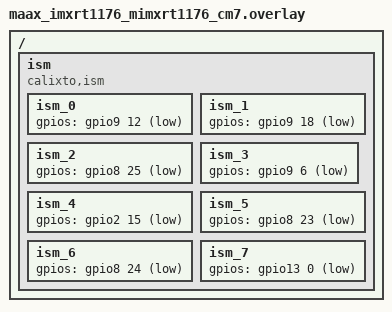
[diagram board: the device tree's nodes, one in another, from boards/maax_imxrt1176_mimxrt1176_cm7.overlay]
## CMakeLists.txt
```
cmake_minimum_required(VERSION 3.20.0)

find_package(Zephyr REQUIRED HINTS $ENV{ZEPHYR_BASE})
project(ism_test)
target_sources(app PRIVATE src/main.c)
```

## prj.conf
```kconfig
CONFIG_ISM=y

CONFIG_ISM_SAMPLE_PERIOD_MS=100
CONFIG_ISM_CONSECUTIVE_SAMPLES=3
CONFIG_ISM_THREAD_STACK_SIZE=1024
CONFIG_ISM_THREAD_PRIORITY=5
CONFIG_ISM_INIT_PRIORITY=90
CONFIG_HEAP_MEM_POOL_SIZE=1024

CONFIG_GPIO=y

CONFIG_LOG=y
CONFIG_LOG_DEFAULT_LEVEL=3

CONFIG_THREAD_NAME=y
```

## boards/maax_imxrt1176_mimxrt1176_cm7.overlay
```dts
    / {
        ism {
            compatible = "calixto,ism";

            ism_0 {
                gpios = <&gpio9 12 GPIO_ACTIVE_LOW>;
            };

            ism_1 {
                gpios = <&gpio9 18 GPIO_ACTIVE_LOW>;
            };

            ism_2 {
                gpios = <&gpio8 25 GPIO_ACTIVE_LOW>;
            };

            ism_3 {
                gpios = <&gpio9 6 GPIO_ACTIVE_LOW>;
            };

            ism_4 {
                gpios = <&gpio2 15 GPIO_ACTIVE_LOW>;
            };

            ism_5 {
                gpios = <&gpio8 23 GPIO_ACTIVE_LOW>;
            };

            ism_6 {
                gpios = <&gpio8 24 GPIO_ACTIVE_LOW>;
            };

            ism_7 {
			    gpios = <&gpio13 0 GPIO_ACTIVE_LOW>;
            };

        };


    };
```

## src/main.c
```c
#include <zephyr/kernel.h>
#include <zephyr/logging/log.h>
#include <zephyr/device.h>

#include "drivers/ism.h"

LOG_MODULE_REGISTER(ism_test, LOG_LEVEL_DBG);


static void ism_ipm_callback(uint8_t channel, uint8_t state)
{
    LOG_INF("ISM CHANGE ch%u -> %s  (confirmed after %u x %u ms)",
            channel,
            state ? "ACTIVE" : "INACTIVE",
            CONFIG_ISM_CONSECUTIVE_SAMPLES,
            CONFIG_ISM_SAMPLE_PERIOD_MS);
}

int main(void)
{
    LOG_INF("ISM test ) starting");
    LOG_INF("Debounce window: %u samples x %u ms = %u ms",
            CONFIG_ISM_CONSECUTIVE_SAMPLES,
            CONFIG_ISM_SAMPLE_PERIOD_MS,
            CONFIG_ISM_CONSECUTIVE_SAMPLES * CONFIG_ISM_SAMPLE_PERIOD_MS);

    const struct device *ism_dev = DEVICE_DT_GET(DT_INST(0, calixto_ism));

    if (!device_is_ready(ism_dev)) {
        LOG_ERR("ISM device not ready");
        return -ENODEV;
    }

    int ret = ISM_init(ism_dev, ism_ipm_callback);
    if (ret != 0) {
        LOG_ERR("ISM_init failed (err %d)", ret);
        return ret;
    }

    LOG_INF("ISM polling active - callback fires on confirmed changes");

    while (true) {
        k_sleep(K_SECONDS(10));

        for (uint8_t ch = 0; ch < 8; ch++) {
            uint16_t state = 0;
            int rd = ISM_rd_chnl_state(ism_dev, ch, &state);

            if (rd == -ENODEV) {
                break;
            } else if (rd == -EAGAIN) {
                LOG_DBG("ch%u: buffer not yet full", ch);
            } else if (rd == 0) {
                LOG_INF("ch%u: last confirmed state = %u", ch, state);
            }
        }
    }

    return 0;
}
```
